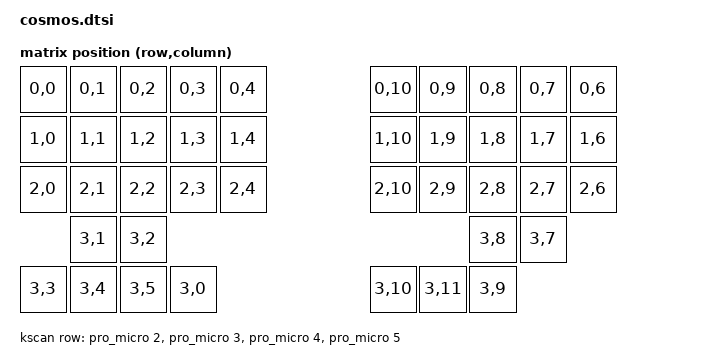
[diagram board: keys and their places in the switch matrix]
// This file was generated from a template. Edit it to match your keyboard.
// See https://zmk.dev/docs/development/hardware-integration/new-shield for more
// instructions.

#include <dt-bindings/zmk/matrix_transform.h>

#include "cosmos-layouts.dtsi"

/ {
    chosen {
        zmk,physical-layout = &default_layout;
    };

    kscan: kscan {
        // If the hardware does not use a switch matrix, change this to the
        // appropriate driver and update the properties below to match.
        // See https://zmk.dev/docs/config/kscan for supported key scan drivers.
        compatible = "zmk,kscan-gpio-matrix";
        // Set this to "col2row" or "row2col" to match the hardware. If using
        // "row2col", change the col-gpios in the _left.overlay and _right.overlay
        // files to (GPIO_ACTIVE_HIGH | GPIO_PULL_DOWN) and the row-gpios here to
        // GPIO_ACTIVE_HIGH.
        diode-direction = "col2row";
        wakeup-source;

        // Rows: same pins on both halves (left pin column, silk 017/020/022/024).
        // PROVISIONAL until wiring is soldered — see keyboard.todo.md.
        row-gpios
            = <&pro_micro 2 (GPIO_ACTIVE_HIGH | GPIO_PULL_DOWN)> // R0 top letter row
            , <&pro_micro 3 (GPIO_ACTIVE_HIGH | GPIO_PULL_DOWN)> // R1 home row
            , <&pro_micro 4 (GPIO_ACTIVE_HIGH | GPIO_PULL_DOWN)> // R2 bottom letter row
            , <&pro_micro 5 (GPIO_ACTIVE_HIGH | GPIO_PULL_DOWN)> // R3 Esc/Tab + thumbs
            ;
    };

    default_transform: default_transform {
        // See https://zmk.dev/docs/development/hardware-integration/new-shield#matrix-transform
        // for how to configure this
        compatible = "zmk,matrix-transform";
        // Per half: 4 rows x 6 cols. C0 = outer pinky column, C4 = inner index
        // column, C5 = thumb-only column. Right half cols are offset by 6.
        // Order below = keymap order (reading left half, then right half).
        columns = <12>;
        rows = <4>;

        map = <
            RC(0,0) RC(0,1) RC(0,2) RC(0,3) RC(0,4)                    RC(0,10) RC(0,9) RC(0,8) RC(0,7) RC(0,6)
            RC(1,0) RC(1,1) RC(1,2) RC(1,3) RC(1,4)                    RC(1,10) RC(1,9) RC(1,8) RC(1,7) RC(1,6)
            RC(2,0) RC(2,1) RC(2,2) RC(2,3) RC(2,4)                    RC(2,10) RC(2,9) RC(2,8) RC(2,7) RC(2,6)
                    RC(3,1) RC(3,2)                                                      RC(3,8) RC(3,7)
            RC(3,3) RC(3,4) RC(3,5) RC(3,0)                            RC(3,10) RC(3,11) RC(3,9)
        >;
    };
};
